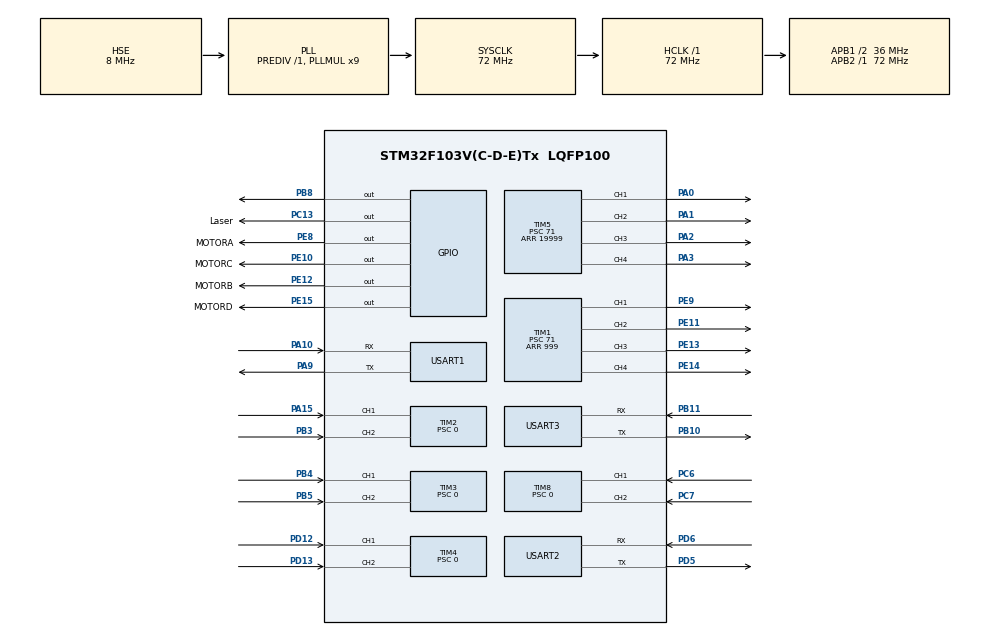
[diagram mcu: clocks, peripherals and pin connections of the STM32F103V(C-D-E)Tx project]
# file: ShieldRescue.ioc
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FREERTOS.Queues01=TaskQueue,5,3,1,Dynamic,NULL,NULL
FREERTOS.Tasks01=defaultTask,24,512,StartDefaultTask,Default,NULL,Dynamic,NULL,NULL;NavTask,48,512,StartNavTask,As weak,NULL,Dynamic,NULL,NULL;ActionTask,24,512,StartActionTask,As weak,NULL,Dynamic,NULL,NULL;MonitorTask,8,256,StartMonitorTask,As weak,NULL,Dynamic,NULL,NULL
FREERTOS.configTOTAL_HEAP_SIZE=10240
Mcu.Family=STM32F1
Mcu.Name=STM32F103V(C-D-E)Tx
Mcu.Package=LQFP100
NVIC.PriorityGroup=NVIC_PRIORITYGROUP_4
NVIC.TIM6_IRQn=true\:15\:0\:false\:false\:true\:false\:false\:true\:true
NVIC.TimeBase=TIM6_IRQn
NVIC.TimeBaseIP=TIM6
NVIC.USART1_IRQn=true\:5\:0\:false\:false\:true\:true\:true\:true\:true
NVIC.USART2_IRQn=true\:5\:0\:false\:false\:true\:true\:true\:true\:true
OSC_IN.Mode=HSE-External-Oscillator
OSC_IN.Signal=RCC_OSC_IN
OSC_OUT.Mode=HSE-External-Oscillator
OSC_OUT.Signal=RCC_OSC_OUT
PA0-WKUP.Signal=S_TIM5_CH1
PA1.Signal=S_TIM5_CH2
PA10.Mode=Asynchronous
PA10.Signal=USART1_RX
PA13.Mode=Serial_Wire
PA13.Signal=SYS_JTMS-SWDIO
PA14.Mode=Serial_Wire
PA14.Signal=SYS_JTCK-SWCLK
PA15.Signal=S_TIM2_CH1_ETR
PA2.Signal=S_TIM5_CH3
PA3.Signal=S_TIM5_CH4
PA9.Mode=Asynchronous
PA9.Signal=USART1_TX
PB10.Mode=Asynchronous
PB10.Signal=USART3_TX
PB11.Mode=Asynchronous
PB11.Signal=USART3_RX
PB3.Signal=S_TIM2_CH2
PB4.Signal=S_TIM3_CH1
PB5.Signal=S_TIM3_CH2
PB8.Signal=GPIO_Output
PC13-TAMPER-RTC.GPIO_Label=Laser 
PC13-TAMPER-RTC.Signal=GPIO_Output
PC6.Signal=S_TIM8_CH1
PC7.Signal=S_TIM8_CH2
PD12.Signal=S_TIM4_CH1
PD13.Signal=S_TIM4_CH2
PD5.Mode=Asynchronous
PD5.Signal=USART2_TX
PD6.Mode=Asynchronous
PD6.Signal=USART2_RX
PE10.GPIO_Label=MOTORC
PE10.Signal=GPIO_Output
PE11.Signal=S_TIM1_CH2
PE12.GPIO_Label=MOTORB
PE12.Signal=GPIO_Output
PE13.Signal=S_TIM1_CH3
PE14.Signal=S_TIM1_CH4
PE15.GPIO_Label=MOTORD
PE15.Signal=GPIO_Output
PE8.GPIO_Label=MOTORA
PE8.Signal=GPIO_Output
PE9.Signal=S_TIM1_CH1
ProjectManager.HeapSize=0x200
ProjectManager.StackSize=0x400
ProjectManager.TargetToolchain=MDK-ARM V5.32
RCC.AHBFreq_Value=72000000
RCC.APB1CLKDivider=RCC_HCLK_DIV2
RCC.APB1Freq_Value=36000000
RCC.APB1TimFreq_Value=72000000
RCC.APB2Freq_Value=72000000
RCC.APB2TimFreq_Value=72000000
RCC.HCLKFreq_Value=72000000
RCC.PLLMUL=RCC_PLL_MUL9
RCC.PLLSourceVirtual=RCC_PLLSOURCE_HSE
RCC.SYSCLKFreq_VALUE=72000000
RCC.SYSCLKSource=RCC_SYSCLKSOURCE_PLLCLK
RCC.USBFreq_Value=72000000
SH.S_TIM1_CH1.0=TIM1_CH1,PWM Generation1 CH1
SH.S_TIM1_CH2.0=TIM1_CH2,PWM Generation2 CH2
SH.S_TIM1_CH3.0=TIM1_CH3,PWM Generation3 CH3
SH.S_TIM1_CH4.0=TIM1_CH4,PWM Generation4 CH4
SH.S_TIM2_CH1_ETR.0=TIM2_CH1,Encoder_Interface
SH.S_TIM2_CH2.0=TIM2_CH2,Encoder_Interface
SH.S_TIM3_CH1.0=TIM3_CH1,Encoder_Interface
SH.S_TIM3_CH2.0=TIM3_CH2,Encoder_Interface
SH.S_TIM4_CH1.0=TIM4_CH1,Encoder_Interface
SH.S_TIM4_CH2.0=TIM4_CH2,Encoder_Interface
SH.S_TIM5_CH1.0=TIM5_CH1,PWM Generation1 CH1
SH.S_TIM5_CH2.0=TIM5_CH2,PWM Generation2 CH2
SH.S_TIM5_CH3.0=TIM5_CH3,PWM Generation3 CH3
SH.S_TIM5_CH4.0=TIM5_CH4,PWM Generation4 CH4
SH.S_TIM8_CH1.0=TIM8_CH1,Encoder_Interface
SH.S_TIM8_CH2.0=TIM8_CH2,Encoder_Interface
TIM1.Channel-PWM\ Generation1\ CH1=TIM_CHANNEL_1
TIM1.Channel-PWM\ Generation2\ CH2=TIM_CHANNEL_2
TIM1.Channel-PWM\ Generation3\ CH3=TIM_CHANNEL_3
TIM1.Channel-PWM\ Generation4\ CH4=TIM_CHANNEL_4
TIM1.Period=999
TIM1.Prescaler=71
TIM2.EncoderMode=TIM_ENCODERMODE_TI12
TIM2.IC1Filter=15
TIM2.IC2Filter=15
TIM2.Prescaler=0
TIM3.EncoderMode=TIM_ENCODERMODE_TI12
TIM3.IC1Filter=15
TIM3.IC2Filter=15
TIM3.Prescaler=0
TIM4.EncoderMode=TIM_ENCODERMODE_TI12
TIM4.IC1Filter=15
TIM4.IC2Filter=15
TIM4.Prescaler=0
TIM5.Channel-PWM\ Generation1\ CH1=TIM_CHANNEL_1
TIM5.Channel-PWM\ Generation2\ CH2=TIM_CHANNEL_2
TIM5.Channel-PWM\ Generation3\ CH3=TIM_CHANNEL_3
TIM5.Channel-PWM\ Generation4\ CH4=TIM_CHANNEL_4
TIM5.Period=19999
TIM5.Prescaler=71
TIM8.EncoderMode=TIM_ENCODERMODE_TI12
TIM8.IC1Filter=15
TIM8.IC2Filter=15
TIM8.Prescaler=0
USART1.VirtualMode=VM_ASYNC
USART2.VirtualMode=VM_ASYNC
USART3.VirtualMode=VM_ASYNC
VP_FREERTOS_VS_CMSIS_V2.Mode=CMSIS_V2
VP_SYS_VS_tim6.Mode=TIM6
board=custom

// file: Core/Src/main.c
/* USER CODE BEGIN Header */
/**
  ******************************************************************************
  * @file           : main.c
  * @brief          : Main program body
  ******************************************************************************
  * @attention
  *
  * Copyright (c) 2026 STMicroelectronics.
  * All rights reserved.
  *
  * This software is licensed under terms that can be found in the LICENSE file
  * in the root directory of this software component.
  * If no LICENSE file comes with this software, it is provided AS-IS.
  *
  ******************************************************************************
  */
/* USER CODE END Header */
#include "main.h"
#include "cmsis_os.h"
#include "tim.h"
#include "usart.h"
#include "gpio.h"

/* USER CODE BEGIN Includes */
#include "global_state.h"
#include "bsp_motor.h"
#include "bsp_servo.h"
#include "bsp_laser.h"
#include "bsp_usart.h"
/* USER CODE END Includes */

void SystemClock_Config(void);
void MX_FREERTOS_Init(void);

int main(void)
{

  /* MCU Configuration--------------------------------------------------------*/

  /* Reset of all peripherals, Initializes the Flash interface and the Systick. */
  HAL_Init();

  /* Configure the system clock */
  SystemClock_Config();

  /* Initialize all configured peripherals */
  MX_GPIO_Init();
  MX_TIM1_Init();
  MX_TIM2_Init();
  MX_TIM3_Init();
  MX_TIM4_Init();
  MX_TIM5_Init();
  MX_TIM8_Init();
  MX_USART1_UART_Init();
  MX_USART2_UART_Init();
  MX_USART3_UART_Init();
  /* USER CODE BEGIN 2 */
Motor_Init();
Servo_Init();
BSP_UART_Init();
  /* USER CODE END 2 */

  /* Init scheduler */
//  osKernelInitialize();  /* Call init function for freertos objects (in cmsis_os2.c) */
//  MX_FREERTOS_Init();

  /* Start scheduler */
//  osKernelStart();

  /* We should never get here as control is now taken by the scheduler */

  /* Infinite loop */
  /* USER CODE BEGIN WHILE */
  while (1)
  {
Chassis_Control_O_Mecanum(200, 0, 0);
    HAL_Delay(2000);
    /* USER CODE END WHILE */

  }
}

void SystemClock_Config(void)
{
  RCC_OscInitTypeDef RCC_OscInitStruct = {0};
  RCC_ClkInitTypeDef RCC_ClkInitStruct = {0};

  /** Initializes the RCC Oscillators according to the specified parameters
  * in the RCC_OscInitTypeDef structure.
  */
  RCC_OscInitStruct.OscillatorType = RCC_OSCILLATORTYPE_HSE;
  RCC_OscInitStruct.HSEState = RCC_HSE_ON;
  RCC_OscInitStruct.HSEPredivValue = RCC_HSE_PREDIV_DIV1;
  RCC_OscInitStruct.HSIState = RCC_HSI_ON;
  RCC_OscInitStruct.PLL.PLLState = RCC_PLL_ON;
  RCC_OscInitStruct.PLL.PLLSource = RCC_PLLSOURCE_HSE;
  RCC_OscInitStruct.PLL.PLLMUL = RCC_PLL_MUL9;
  if (HAL_RCC_OscConfig(&RCC_OscInitStruct) != HAL_OK)
  {
    Error_Handler();
  }

  /** Initializes the CPU, AHB and APB buses clocks
  */
  RCC_ClkInitStruct.ClockType = RCC_CLOCKTYPE_HCLK|RCC_CLOCKTYPE_SYSCLK
                              |RCC_CLOCKTYPE_PCLK1|RCC_CLOCKTYPE_PCLK2;
  RCC_ClkInitStruct.SYSCLKSource = RCC_SYSCLKSOURCE_PLLCLK;
  RCC_ClkInitStruct.AHBCLKDivider = RCC_SYSCLK_DIV1;
  RCC_ClkInitStruct.APB1CLKDivider = RCC_HCLK_DIV2;
  RCC_ClkInitStruct.APB2CLKDivider = RCC_HCLK_DIV1;

  if (HAL_RCC_ClockConfig(&RCC_ClkInitStruct, FLASH_LATENCY_2) != HAL_OK)
  {
    Error_Handler();
  }
}

void HAL_TIM_PeriodElapsedCallback(TIM_HandleTypeDef *htim)
{
  if (htim->Instance == TIM6)
  {
    HAL_IncTick();
  }
}

void Error_Handler(void)
{
  __disable_irq();
  while (1)
  {
  }
}
